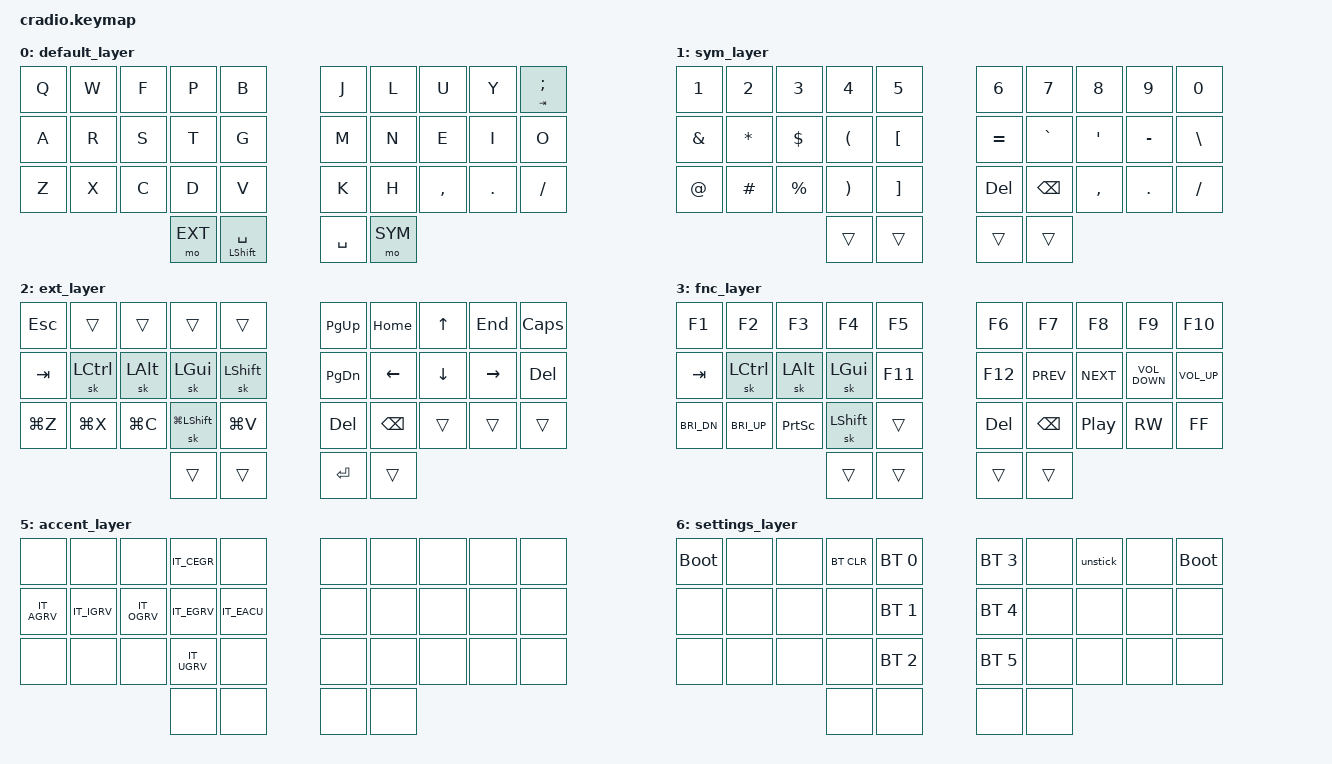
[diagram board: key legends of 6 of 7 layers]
/*
 * Copyright (c) 2020 The ZMK Contributors
 *
 * SPDX-License-Identifier: MIT
 */

#include <behaviors.dtsi>
#include <dt-bindings/zmk/keys.h>
#include <dt-bindings/zmk/bt.h>
#include "keymap_italian.h"

// Layer definitions
    #define BASE 0
    #define SYM 1
    #define EXT 2
    #define FNC 3
    #define SYM2 4
    #define ACCENT 5
		#define SETTINGS 6
// -----------------

&mt {
   //  flavor = "tap-preferred";
   // tapping_term_ms = <200>;
};

&sk {
    quick-release;
    ignore-modifiers;
};

/ {
	macros {
		// sometimes my device thinks a modifier is being held down
		// pressing all modifiers fixes it.
		unstick: unstick {
			label = "ZM_unstick";
			compatible = "zmk,behavior-macro";
			#binding-cells = <0>;
			bindings = <&kp LSHIFT &kp RSHIFT &kp LCTRL &kp RCTRL &kp LALT &kp RALT &kp LGUI &kp RGUI>;
			};
	};
	combos {
		compatible = "zmk,combos";
		// both right thumb keys
        	combo_accent {
            		timeout-ms = <300>;
            		key-positions = <32 33>;
            		bindings = <&mo ACCENT>;
        		};
		// internal-left & external-right thumb keys
		combo_sym2 {
			timeout-ms = <200>;
			key-positions = <31 33>;
			bindings = <&mo SYM2>;
			};
		// both left thumb keys
		combo_settings {
			timeout-ms = <300>;
			key-positions = <30 31>;
			bindings = <&mo SETTINGS>;
			};
    	};

    	conditional_layers {
        	compatible = "zmk,conditional-layers";
        	tri_layer {
            		if-layers = <SYM EXT>;
            		then-layer = <FNC>;
        	};
    	};
    	behaviors {
        	tui: tui {
            		compatible = "zmk,behavior-hold-tap";
            		#binding-cells = <2>;
            		flavor = "tap-unless-interrupted";
            		tapping-term-ms = <100>;                        // <---[[produces tap if held longer than tapping-term-ms]]
            		quick-tap-ms = <200>;
            		bindings = <&kp>, <&kp>;
            		// hold-trigger-key-positions = <5 6 7 8 9 10>;    // <---[[right-hand keys]]
        	};
    	};

    keymap {
            compatible = "zmk,keymap";

        // Base alpha layer
       		default_layer {
		bindings = <
		&kp Q &kp W &kp F &kp P &kp B           &kp J &kp L  &kp U &kp Y &mt TAB SEMI
		&kp A &kp R &kp S &kp T &kp G           &kp M &kp N  &kp E &kp I &kp O
		&kp Z &kp X &kp C &kp D &kp V           &kp K &kp H  &kp COMMA &kp DOT &kp SLASH
             &mo EXT &mt LSHIFT SPACE           &kp SPACE &mo SYM
		>;
		};

        // Numbers and high frequency symbols
       		sym_layer {
		bindings = <
		&kp N1 &kp N2 &kp N3 &kp N4 &kp N5		  	&kp N6 &kp N7 &kp N8 &kp N9 &kp N0
		&kp AMPS &kp ASTRK &kp DOLLAR &kp LPAR &kp LBKT 	  	&kp EQUAL &kp GRAVE &kp SQT &kp MINUS &kp BSLH
		&kp AT &kp HASH &kp PERCENT &kp RPAR &kp RBKT		&kp DEL &kp BSPC &kp COMMA &kp DOT &kp SLASH
					   &trans  &trans      	&trans &trans
		>;
		};

        // Main modifiers and arrow keys
		    ext_layer {
		bindings = <
		&kp ESC  &trans &trans  &trans  &trans    			&kp PG_UP  &kp HOME &kp UP &kp END &kp CAPS
		&kp TAB &sk LCTRL  &sk LALT  &sk LGUI  &sk LSHIFT 		&kp PG_DN &kp LEFT  &kp DOWN  &kp RIGHT   &kp DEL
		&kp LG(Z)  &kp LG(X) &kp LG(C) &sk LG(LSHIFT)  &kp LG(V)         	&kp DEL &kp BSPC &trans &trans  &trans
					        &trans &trans        	&kp ENTER  &trans 
		>;
		};

        // Function keys with modifiers
       		fnc_layer {
		bindings = <
		&kp F1 &kp F2 &kp F3 &kp F4 &kp F5                  			&kp F6 &kp F7 &kp F8 &kp F9 &kp F10 
		&kp TAB &sk LCTRL &sk LALT &sk LGUI &kp F11    				&kp F12 &kp C_PREV  &kp C_NEXT &kp C_VOLUME_DOWN &kp C_VOL_UP
		&kp C_BRI_DN &kp C_BRI_UP &kp PRINTSCREEN &sk LSHIFT &trans		&kp DEL &kp BSPC &kp C_PP &kp C_RW &kp C_FF
          				           &trans &trans              &trans &trans  
		>;
		};

        // Low frequency symbols.
       		symbols_2_layer {
		bindings = <
		&kp EXCL &kp AT &kp HASH &kp DOLLAR &kp PERCENT         &kp CARET &kp AMPS &kp ASTRK &none &kp COLON
		&none &none &none &none &kp LBRC 		        	&kp PLUS &kp TILDE &kp DQT &kp UNDER &kp PIPE
		&none &none &none &none &kp RBRC 	        	&kp DEL &kp BSPC &kp LT &kp GT &kp QUESTION
          				     &none &none                         &none &none           				           												&none &none        	&none &none 
		>;
		};

        // Used to type regional accents.
       		accent_layer {
		bindings = <
		&none &none &none &kp IT_CEGR &none                         &none &none &none &none &none 
		&kp IT_AGRV &kp IT_IGRV &kp IT_OGRV &kp IT_EGRV &kp IT_EACU &none &none &none &none &none
		&none &none &none &kp IT_UGRV &none                         &none &none &none &none &none
          				     &none &none                         &none &none 
		>;
		};

        // Used to change the keyboard's settings.
       		settings_layer {
		bindings = <
		&bootloader &none &none &bt BT_CLR &bt BT_SEL 0         &bt BT_SEL 3 &none &unstick &none &bootloader 
		&none &none &none &none      &bt BT_SEL 1 		&bt BT_SEL 4 &none &none &none &none
		&none &none &none &none      &bt BT_SEL 2               &bt BT_SEL 5 &none &none &none &none
          				     &none &none                         &none &none 
		>;
		};
        
	};
};
